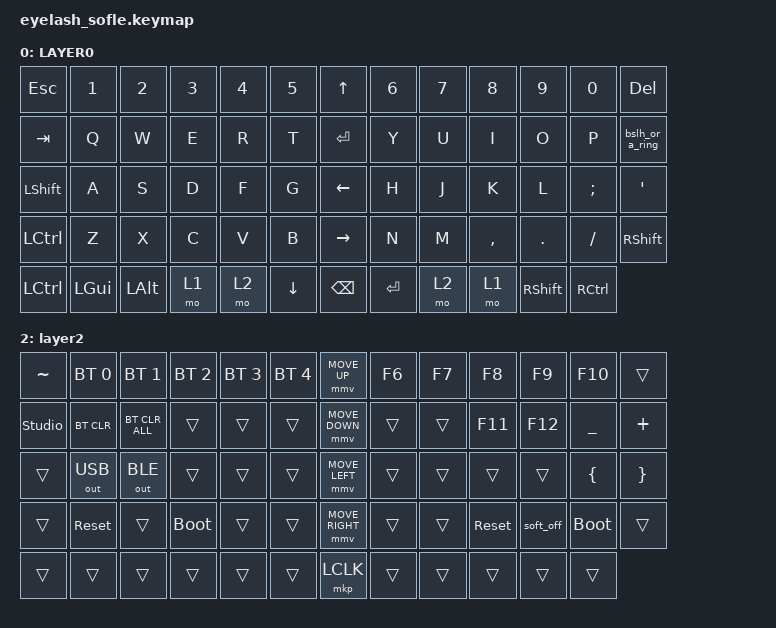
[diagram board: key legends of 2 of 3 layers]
/*
 * Copyright (c) 2020 The ZMK Contributors
 *
 * SPDX-License-Identifier: MIT
 */

#include <behaviors.dtsi>
#include <dt-bindings/zmk/bt.h>
#include <dt-bindings/zmk/keys.h>
#include <dt-bindings/zmk/mouse.h>
#include <dt-bindings/zmk/outputs.h>
#include <dt-bindings/zmk/rgb.h>

#include <input/processors.dtsi>

#define ZMK_MOUSE_DEFAULT_MOVE_VAL 1200  // 600
#define ZMK_MOUSE_DEFAULT_SCRL_VAL 20    // 10

/ {
    behaviors {
        mmv {
            acceleration-exponent = <1>;     // 1
            time-to-max-speed-ms = <900>;  // 40
            delay-ms = <0>;                  // 0
        };

        msc {
            acceleration-exponent = <1>;     // 0
            time-to-max-speed-ms = <400>;    // 500
            delay-ms = <0>;                  // 10
        };

        // --- THIS IS YOUR NEW, FIXED BEHAVIOR ---
        bslh_or_a_ring: bslh_or_a_ring {
            compatible = "zmk,behavior-mod-morph";
            label = "BSLH_OR_A_RING";
            #binding-cells = <0>;

            // 1. Normal press: Backslash
            // 2. Alt-press: Sends "Alt + Left Bracket"
            bindings = <&kp BSLH>, <&kp RALT(LBRC)>;
            mods = <(MOD_LALT | MOD_RALT)>;
        };
    };

    scroll_encoder: scroll_encoder {
        compatible = "zmk,behavior-sensor-rotate";
        #sensor-binding-cells = <0>;
        bindings = <&msc SCRL_DOWN>, <&msc SCRL_UP>;

        tap-ms = <30>;
    };

    keymap {
        compatible = "zmk,keymap";

        // --- THIS IS YOUR NEW layer0 (FROM IMAGE 1) ---
        layer0 {
            bindings = <
&kp ESC   &kp N1    &kp N2    &kp N3    &kp N4    &kp N5        &kp UP_ARROW      &kp N6    &kp N7    &kp N8    &kp N9    &kp N0    &kp DELETE
&kp TAB   &kp Q     &kp W     &kp E     &kp R     &kp T         &kp ENTER         &kp Y     &kp U     &kp I     &kp O     &kp P     &bslh_or_a_ring
&kp LSHFT &kp A     &kp S     &kp D     &kp F     &kp G         &kp LEFT_ARROW    &kp H     &kp J     &kp K     &kp L     &kp SEMI  &kp APOS
&kp LCTRL &kp Z     &kp X     &kp C     &kp V     &kp B         &kp RIGHT_ARROW   &kp N     &kp M     &kp COMMA &kp DOT   &kp FSLH  &kp RSHFT
&kp LCTRL &kp LGUI  &kp LALT  &mo 1     &mo 2     &kp DOWN_ARROW    &kp BACKSPACE &kp ENTER &mo 2     &mo 1     &kp RSHFT &kp RCTRL
            >;

            // Encoder mapping for this layer
            sensor-bindings = <&inc_dec_kp C_VOLUME_UP C_VOL_DN>;
            display-name = "LAYER0";
        };

        // --- THIS IS YOUR NEW layer_1 (FROM IMAGE 2, WITH TRANSPARENT KEYS) ---
        layer_1 {
            bindings = <
&kp GRAVE &kp F1    &kp F2    &kp F3    &kp F4    &kp F5        &trans      &kp F6    &kp F7    &kp F8    &kp F9    &kp F10   &trans
&kp CAPS  &trans    &trans    &trans    &trans    &trans        &trans      &kp PG_UP &kp UP    &kp END   &trans    &kp MINUS &kp EQUAL
&trans    &trans    &trans    &trans    &trans    &trans        &trans      &kp PG_DN &kp LEFT  &kp DOWN  &kp RIGHT &trans    &kp LBRC &kp RBRC
&trans    &trans    &trans    &trans    &trans    &trans        &trans      &trans    &trans    &kp INS   &kp F11   &kp F12   &trans
&trans    &trans    &trans    &trans    &trans    &trans        &trans      &trans    &trans    &trans    &trans    &trans
            >;

            display-name = "layer1";
            sensor-bindings = <&scroll_encoder>;
        };

        // --- THIS IS YOUR ORIGINAL layer_2 (SYSTEM LAYER) ---
        layer_2 {
            bindings = <
&kp TILDE &bt BT_SEL 0  &bt BT_SEL 1  &bt BT_SEL 2  &bt BT_SEL 3  &bt BT_SEL 4    &mmv MOVE_UP      &kp F6  &kp F7  &kp F8    &kp F9    &kp F10   &trans
&studio_unlock    &bt BT_CLR    &bt BT_CLR_ALL  &trans        &trans        &trans          &mmv MOVE_DOWN    &trans  &trans  &kp F11   &kp F12   &kp UNDER &kp PLUS
&trans    &out OUT_USB  &out OUT_BLE  &trans        &trans        &trans          &mmv MOVE_LEFT     &trans  &trans  &trans    &trans    &kp LBRC  &kp RBRC
&trans    &sys_reset  &trans        &bootloader   &trans        &trans          &mmv MOVE_RIGHT   &trans  &trans  &sys_reset &soft_off &bootloader &trans
&trans    &trans      &trans        &trans        &trans        &trans          &mkp LCLK         &trans  &trans  &trans    &trans    &trans
            >;

            display-name = "layer2";
            sensor-bindings = <&scroll_encoder>;
        };
    };
};
